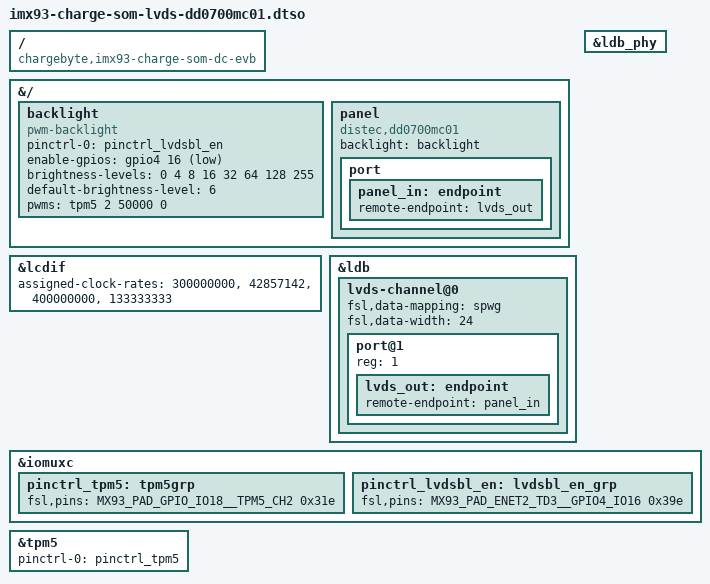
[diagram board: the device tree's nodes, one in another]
// SPDX-License-Identifier: GPL-2.0
/*
 * Copyright (C) 2025 chargebyte GmbH
 * Author: Stefan Wahren <stefan.wahren@chargebyte.com>
 */

#include <dt-bindings/gpio/gpio.h>
#include "imx93-pinfunc.h"

/dts-v1/;
/plugin/;

/ {
	compatible = "chargebyte,imx93-charge-som-dc-evb";
};

&{/} {
	backlight: backlight {
		compatible = "pwm-backlight";
		pinctrl-names = "default";
		pinctrl-0 = <&pinctrl_lvdsbl_en>;
		enable-gpios = <&gpio4 16 GPIO_ACTIVE_LOW>;
		brightness-levels= <0 4 8 16 32 64 128 255>;
		default-brightness-level = <6>;
		pwms = <&tpm5 2 50000 0>;
	};

	panel {
		compatible = "distec,dd0700mc01";
		backlight = <&backlight>;

		port {
			panel_in: endpoint {
				remote-endpoint = <&lvds_out>;
			};
		};
	};
};

&lcdif {
	assigned-clock-rates = <300000000>, <42857142>, <400000000>, <133333333>;
	status = "okay";
};

&ldb {
	status = "okay";

	lvds-channel@0 {
		#address-cells = <1>;
		#size-cells = <0>;
		fsl,data-mapping = "spwg";
		fsl,data-width = <24>;
		status = "okay";

		port@1 {
			reg = <1>;

			lvds_out: endpoint {
				remote-endpoint = <&panel_in>;
			};
		};
	};
};

&ldb_phy {
	status = "okay";
};

&iomuxc {
	pinctrl_tpm5: tpm5grp {
		fsl,pins = <
			MX93_PAD_GPIO_IO18__TPM5_CH2		0x31e
		>;
	};
	
	pinctrl_lvdsbl_en: lvdsbl_en_grp {
		fsl,pins = <
			MX93_PAD_ENET2_TD3__GPIO4_IO16		0x39e
		>;
	};
};

&tpm5 {
	pinctrl-names = "default";
	pinctrl-0 = <&pinctrl_tpm5>;
	status = "okay";
};
